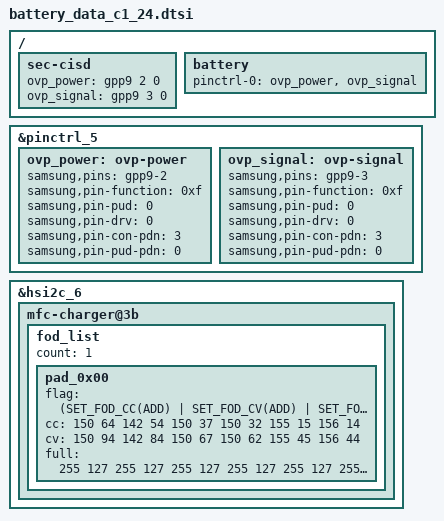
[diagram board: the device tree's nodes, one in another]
/*
 * SAMSUNG UNIVERSAL9830 board device tree source
 *
 * Copyright (c) 2018 Samsung Electronics Co., Ltd.
 *		http://www.samsung.com
 *
 * This program is free software; you can redistribute it and/or modify
 * it under the terms of the GNU General Public License version 2 as
 * published by the Free Software Foundation.
 */

#include "battery_data_c1_common.dtsi"
&pinctrl_5 {
	ovp_power: ovp-power {
		samsung,pins = "gpp9-2";
		samsung,pin-function = <0xf>;
		samsung,pin-pud = <0>;
		samsung,pin-drv = <0>;
		samsung,pin-con-pdn = <3>;
		samsung,pin-pud-pdn = <0>;
	};

	ovp_signal: ovp-signal {
		samsung,pins = "gpp9-3";
		samsung,pin-function = <0xf>;
		samsung,pin-pud = <0>;
		samsung,pin-drv = <0>;
		samsung,pin-con-pdn = <3>;
		samsung,pin-pud-pdn = <0>;
	};
};

/ {
	fragment@battery {
		target-path = "/";
		__overlay__ {
			sec-cisd {
				ovp_power = <&gpp9 2 0>;
				ovp_signal = <&gpp9 3 0>;
			};

			battery {
				pinctrl-names = "default";
				pinctrl-0 = <&ovp_power &ovp_signal>;
			};
		}; /* end of __overlay__ */
	}; /* end of fragment */
};

#define FOD_FLAG_NONE			0
#define FOD_FLAG_ADD			1
#define FOD_FLAG_USE_CC			2
#define FOD_FLAG_USE_DEFAULT	3
#define SET_FOD_CC(_flag)		(FOD_FLAG_ ##_flag)
#define SET_FOD_CV(_flag)		(FOD_FLAG_ ##_flag << 4)
#define SET_FOD_FULL(_flag)		(FOD_FLAG_ ##_flag << 8)

&hsi2c_6 {
	mfc-charger@3b {
		fod_list {
			count = <1>;

			pad_0x00 { /* DEFAULT */
				flag = <(SET_FOD_CC(ADD) | SET_FOD_CV(ADD) | SET_FOD_FULL(ADD))>;
				cc = <150 64 142 54 150 37 150 32 155 15 156 14>;
				cv = <150 94 142 84 150 67 150 62 155 45 156 44>;
				full = <255 127 255 127 255 127 255 127 255 127 255 127>;
			};
		};
	};
};
